# RL6678_IP_SVD register map
Vendor: Realtek
Registers are 32-bit, read-write, reset 0x0 unless marked. A register's access mark holds for its fields unless they carry their own. Offsets are from the block's base; [hi:lo] are bit positions; <NAME> marks a mode.

## REGU_REG
Base 0x42008100
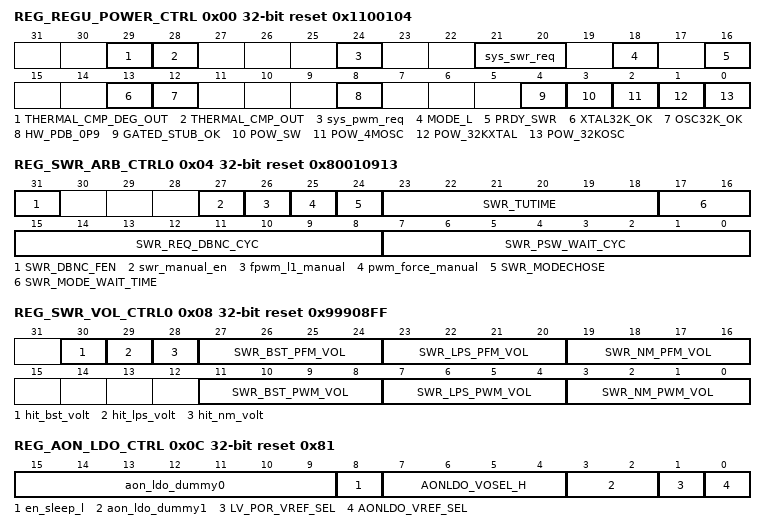
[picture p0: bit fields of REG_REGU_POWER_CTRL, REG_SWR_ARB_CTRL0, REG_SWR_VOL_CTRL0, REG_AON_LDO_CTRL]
0x00 REG_REGU_POWER_CTRL access per field reset 0x1100104
  [29] THERMAL_CMP_DEG_OUT ro — For SWR debug only
  [28] THERMAL_CMP_OUT ro — For SWR debug only
  [24] sys_pwm_req rw — system request SWR mode. 0: PFM 1: PWM
  [21:20] sys_swr_req rw — system request SWR voltage. 00: LPS vol 01: Normal vol 10/11: Burst vol
  [18] MODE_L ro — SWR current mode for debug
  [16] PRDY_SWR ro — SWR power ready flag by analog
  [13] XTAL32K_OK ro
  [12] OSC32K_OK ro — OSC128K ok
  [8] HW_PDB_0P9 rw — Digital control AIP 3.3v power down 1: enable 0: power down
  [4] GATED_STUB_OK rw — No used
  [3] POW_SW rw — 1: power SWR for digital core Note: this bit will be clear by bor/thm reset, and AON PMC will reboot.
  [2] POW_4MOSC rw — 1: power AON 4M osc
  [1] POW_32KXTAL rw — 1: power AON external 32xtal
  [0] POW_32KOSC rw — 1: power AON 128k osc for SDM
0x04 REG_SWR_ARB_CTRL0 reset 0x80010913
  [31] SWR_DBNC_FEN — SWR arb debounce enable
  [27] swr_manual_en — SWR manual mode enable. In manual mode,SWR's PFM vol value use normal pfm vol register,PWM vol use normal pwm vol register
  [26] fpwm_l1_manual — PWM/PFM manual (original fpwm_l1)
  [25] pwm_force_manual — force pwm bias manual (original pwm_force)
  [24] SWR_MODECHOSE — SWR arb voltage adjustment control signal option 0:arb internal signal 1:aip real signal
  [23:18] SWR_TUTIME — Because using AON 100k clock, this can set to 0
  [17:16] SWR_MODE_WAIT_TIME — 00: 50u 01: 100u 10: 250u 11: 500us
  [15:8] SWR_REQ_DBNC_CYC — Arbit dbc time for every step change . The real time is 10us * (this value + 1)
  [7:0] SWR_PSW_WAIT_CYC — Stable time for every step change . The real time is 10us * (this value + 1)
0x08 REG_SWR_VOL_CTRL0 access per field reset 0x99908FF
  [30] hit_bst_volt ro — Current voltage is in bst setting.
  [29] hit_lps_volt ro — Current voltage is in lps setting.
  [28] hit_nm_volt ro — Current voltage is in nm setting.
  [27:24] SWR_BST_PFM_VOL rw — Same as SWR_NM_PFM_VOL
  [23:20] SWR_LPS_PFM_VOL rw — Same as SWR_NM_PFM_VOL
  [19:16] SWR_NM_PFM_VOL rw — SWR/LDO 0000 0.752 0001 0.78 0010 0.801 0011 0.821 0100 0.841 0101 0.861 0110 0.881 0111 0.901 1000 0.921 1001 0.942 1010 0.963 1011 0.985 1100 1.010 1101 1.035 1110 1.062 1111 1.123
  [11:8] SWR_BST_PWM_VOL rw — Same as SWR_NM_PWM_VOL
  [7:4] SWR_LPS_PWM_VOL rw — Same as SWR_NM_PWM_VOL
  [3:0] SWR_NM_PWM_VOL rw — VREF 0.6V 0.575V 0000 0.711 0.682 0001 0.727 0.696 0010 0.761 0.730 0011 0.800 0.767 0100 0.833 0.798 0101 0.857 0.821 0110 0.881 0.844 0111 0.908 0.870 1000 0.937 0.898 1001 0.966 0.926 1010 1.000 0.958 1011 1.031 0.987 1100 1.063 1.018 1101 1.094 1.048 1110 1.123 1.076 1111 1.181 1.131
0x0C REG_AON_LDO_CTRL reset 0x81
  [15:9] aon_ldo_dummy0 — // [REGU][AONLDO] dummy
  [8] en_sleep_l — Enable LDO09H sleep mode 0 : disable (default) 1 : enable
  [7:4] AONLDO_VOSEL_H — AONLDO09 voltage select VREF 0P600V 0P575V 0000: 0.600V 0.575V 0001: 0.715V 0.685V 0010: 0.747V 0.716V 0011: 0.781V 0.749V 0100: 0.820V 0.786V 0101: 0.840V 0.806V 0110: 0.862V 0.826V 0111: 0.885V 0.848V 1000: 0.909V 0.871V 1001: 0.934V 0.896V 1010: 0.961V 0.921V 1011: 0.989V 0.949V 1100: 1.020V 0.977V 1101: 1.052V 1.009V 1110: 1.086V 1.041V 1111: 1.122V 1.076V
  [3:2] aon_ldo_dummy1 — // [REGU][AONLDO] dummy
  [1] LV_POR_VREF_SEL — LV_POR VREF 0 (default) VREF = 0P600V 1 VREF = 0P450V
  [0] AONLDO_VREF_SEL — AONLDO VREF_SEL 0 (default) VREF = 0P600V 1 VREF = 0P575V
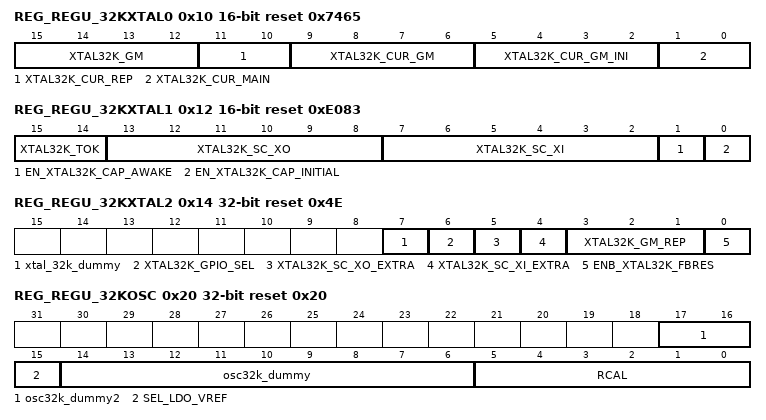
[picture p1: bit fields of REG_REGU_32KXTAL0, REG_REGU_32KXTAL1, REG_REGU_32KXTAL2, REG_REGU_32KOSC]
0x10 REG_REGU_32KXTAL0 16-bit reset 0x7465
  [15:12] XTAL32K_GM — // [RF][32KXTAL] REG_CTRL // gm size
  [11:10] XTAL32K_CUR_REP — // [RF][32KXTAL] REG_CTRL // replica buffer current
  [9:6] XTAL32K_CUR_GM — // [RF][32KXTAL] REG_CTRL // awake gm current, 7pXtal: 0100
  [5:2] XTAL32K_CUR_GM_INI — // [RF][32KXTAL] REG_CTRL // initial gm current, 7pXtal: 0100
  [1:0] XTAL32K_CUR_MAIN — // [RF][32KXTAL] REG_CTRL // xtal main current
0x12 REG_REGU_32KXTAL1 16-bit reset 0xE083
  [15:14] XTAL32K_TOK — // [RF][32KXTAL] REG_CTRL // 00: 100ms 01:200ms 10:400ms 11: 800ms
  [13:8] XTAL32K_SC_XO — // [RF][32KXTAL] REG_CTRL // xo cap
  [7:2] XTAL32K_SC_XI — // [RF][32KXTAL] REG_CTRL // xi cap
  [1] EN_XTAL32K_CAP_AWAKE — // [RF][32KXTAL] REG_CTRL // internal cap enable as awake
  [0] EN_XTAL32K_CAP_INITIAL — // [RF][32KXTAL] REG_CTRL // internal cap enable as initial
0x14 REG_REGU_32KXTAL2 reset 0x4E
  [7] xtal_32k_dummy — // [RF][32KXTAL] REG_CTRL // dummy
  [6] XTAL32K_GPIO_SEL — // [RF][32KXTAL] REG_CTRL // 0: 32K 1: GPIO
  [5] XTAL32K_SC_XO_EXTRA — // [RF][32KXTAL] REG_CTRL // 0: w/i 2.8pF cap 1: w/o 2.8pF cap
  [4] XTAL32K_SC_XI_EXTRA — // [RF][32KXTAL] REG_CTRL // 0: w/i 2.8pF cap 1: w/o 2.8pF cap
  [3:1] XTAL32K_GM_REP — // [RF][32KXTAL] REG_CTRL // repilca size
  [0] ENB_XTAL32K_FBRES — // [RF][32KXTAL] REG_CTRL // 0: enable feedback resistor
0x20 REG_REGU_32KOSC reset 0x20
  [17:16] osc32k_dummy2 — HW used only , these are for reserved
  [15] SEL_LDO_VREF — // [RF][32KOSC] REG_CTRL // 0: LDO low valtage setting 1:high voltage
  [14:6] osc32k_dummy — // [RF][32KOSC] REG_CTRL // dummy
  [5:0] RCAL — // [RF][32KOSC] REG_CTRL // osc frequency is highier as RCAL's larger
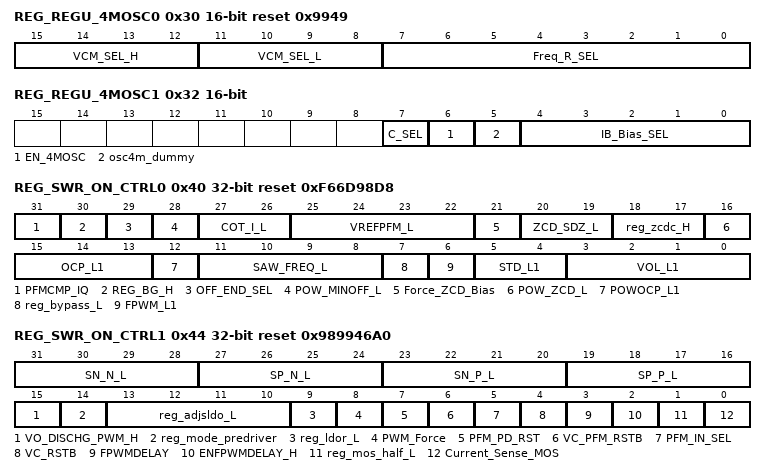
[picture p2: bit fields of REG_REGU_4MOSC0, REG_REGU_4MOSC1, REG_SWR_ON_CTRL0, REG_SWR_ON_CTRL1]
0x30 REG_REGU_4MOSC0 16-bit reset 0x9949
  [15:12] VCM_SEL_H — // [RF][4MOSC] REG_CTRL
  [11:8] VCM_SEL_L — // [RF][4MOSC] REG_CTRL
  [7:0] Freq_R_SEL — // [RF][4MOSC] REG_CTRL
0x32 REG_REGU_4MOSC1 16-bit access per field
  [7] C_SEL rw — // [RF][4MOSC] REG_CTRL
  [6] EN_4MOSC ro — // [RF][4MOSC] 1'b1 : enable Controlley by HW function .
  [5] osc4m_dummy rw — // [RF][4MOSC] REG_CTRL
  [4:0] IB_Bias_SEL rw — // [RF][4MOSC] REG_CTRL
0x40 REG_SWR_ON_CTRL0 access per field reset 0xF66D98D8
  [31] PFMCMP_IQ rw — PFM comparator bias 0: 50nA 1: 250nA
  [30] REG_BG_H rw — 1: VREF=0.6 0: VREF=0.575
  [29] OFF_END_SEL rw — COT off time controlled by 0: ZCD 1: min off time
  [28] POW_MINOFF_L rw — 0: normal current 1: increase OCP cmp current
  [27:26] COT_I_L rw — COT ON Current 00: 150nA 01: 150nA+100nA 10: 150nA+150nA 11: 150nA+250nA
  [25:22] VREFPFM_L ro — SWR/LDO 0000: 0.55 0001: 0.60 0010: 0.65 0011: 0.70 0100: 0.75 0101: 0.80 0110: 0.85 0111: 0.90 1000: 0.95 1001: 1.00 1010: 1.05 1011: 1.10 1100: 1.10 1101: 1.10 1110: 1.10 1111: 1.10
  [21] Force_ZCD_Bias rw — 0: ZCD bias on after SS 1: ZCD bias on when ZCD enable
  [20:19] ZCD_SDZ_L rw — Increase ZCD delay cell
  [18:17] reg_zcdc_H rw — 00: 0.1u 01: 0.2u(PFM) 10: 0.7u(PWM) 11: 0.8u PMW mode parameter when system is high load
  [16] POW_ZCD_L rw — Enable ZCD
  [15:13] OCP_L1 rw — PWM current(A) PFM current(A) mP 000 0.5712 0.0816 001 0.6528 0.1224 010 0.7344 0.1632 011 0.816 0.2448 100 0.8976 0.3264 101 0.9792 0.408 110 1.0608 0.4896 111 1.1424 VIN/10
  [12] POWOCP_L1 rw — POWOCP_L1=1=> enable over current protection
  [11:8] SAW_FREQ_L rw — 0000 458.0k 0001 680.2k 0010 898.9k 0011 1.113M 0100 1.321M 0101 1.522M 0110 1.716M 0111 1.902M 1000 2.087M 1001 2.258M 1010 2.426M 1011 2.582M 1100 2.743M 1101 2.888M 1110 3.035M 1111 3.165M PMW mode parameter when system is high load
  [7] reg_bypass_L rw — 1: bypass SSR latch
  [6] FPWM_L1 ro — FPWM_L1 = 1: force PWM FPWM_L1 = 0: force PFM
  [5:4] STD_L1 rw — STD_L1<1:0> time 750u 1.5m 10: 3m 11: 6m
  [3:0] VOL_L1 ro — VREF 0.6V 0.575V 0000 0.595 0.570 0001 0.709 0.679 0010 0.740 0.709 0011 0.774 0.742 0100 0.812 0.778 0101 0.833 0.798 0110 0.854 0.818 0111 0.876 0.840 1000 0.900 0.863 1001 0.925 0.886 1010 0.951 0.912 1011 0.979 0.939 1100 1.009 0.967 1101 1.041 0.997 1110 1.074 1.029 1111 1.110 1.064
0x44 REG_SWR_ON_CTRL1 access per field reset 0x989946A0
  [31:28] SN_N_L rw — NGATE NMOS driving
  [27:24] SP_N_L rw — NGATE PMOS driving
  [23:20] SN_P_L rw — PGATE NMOS driving
  [19:16] SP_P_L rw — PGATE PMOS driving
  [15] VO_DISCHG_PWM_H rw — 1: dummy loading 5mA
  [14] reg_mode_predriver rw — 1: 3 level predriver
  [13:10] reg_adjsldo_L rw — 0000: 0.735 0001: 0.742 0010: 0.750 0011: 0.766 0100: 0.783 0101: 0.800 0110: 0.818 0111: 0.837 1000: 0.857 1001: 0.878 1010: 0.900 1011: 0.923 1100: 0.947 1101: 0.973 1110: 1.029 1111: 1.091
  [9] reg_ldor_L rw — 1: ldos res short
  [8] PWM_Force ro — 0: PWM bias enabled only at PWM mode 1: Force PWM bias enable when in PWM/PFM mode
  [7] PFM_PD_RST rw — 1: When leave PFM mode, COT logic is reset
  [6] VC_PFM_RSTB rw — When into PFM, VC is 0: clamped (bit 40 also =1) 1: floating
  [5] PFM_IN_SEL rw — Power MOS into PFM when PFM CTRL, 0: rising 1: falling
  [4] VC_RSTB rw — Before SS VC is 0: pulled low 1: floating
  [3] FPWMDELAY rw — 1: PFM<=>PWM PFM/PWM change by using DFF (CKMOD)
  [2] ENFPWMDELAY_H rw — 1: PFM=>PWM delay PWM enable and wait one clock cycle then PFM off
  [1] reg_mos_half_L rw — 1: power mos half PMW mode parameter when system is high load
  [0] Current_Sense_MOS rw — 1: current sensing MOS for large OC current
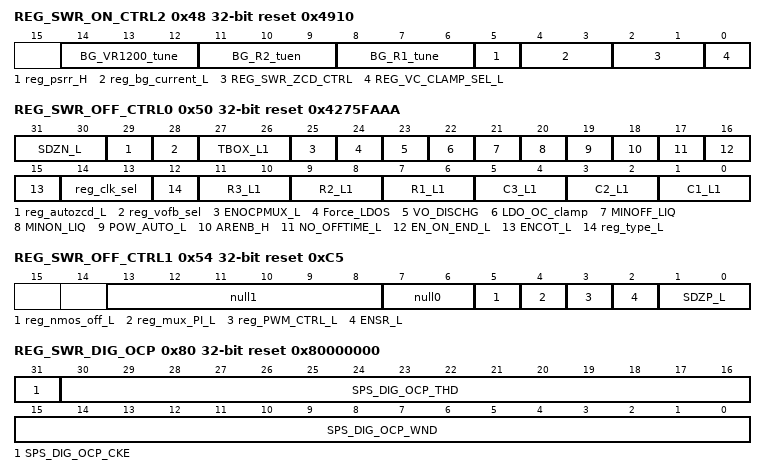
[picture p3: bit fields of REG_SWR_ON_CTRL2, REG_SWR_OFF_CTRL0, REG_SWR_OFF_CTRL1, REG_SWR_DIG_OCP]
0x48 REG_SWR_ON_CTRL2 reset 0x4910
  [14:12] BG_VR1200_tune — BG
  [11:9] BG_R2_tuen — BG R2
  [8:6] BG_R1_tune — BG R1
  [5] reg_psrr_H — 0: default 1: res+cap PMW mode parameter when system is high load
  [4:3] reg_bg_current_L — 00: 23.9n 01: 54.6n 10: 117.8n
  [2:1] REG_SWR_ZCD_CTRL — // SWR ZCD CTRL control <1>1: double current <0>1'b1: force in CCM/DCM boundary mode(default), 1'b0 : no boundary PMW mode parameter when system is high load
  [0] REG_VC_CLAMP_SEL_L — 0: unity gain feedback clamp VC=VREF 1: orignal clamp (roll back option)
0x50 REG_SWR_OFF_CTRL0 reset 0x4275FAAA
  [31:30] SDZN_L — Nonoverlap delay cell for NMOS
  [29] reg_autozcd_L — 0: register 1: 10000
  [28] reg_vofb_sel — 0: vo15 1: LX_SPS
  [27:26] TBOX_L1 — TBOX_L1<1:0> output 00: CKOVER/RAMPOVER 01: NI/PI 10: CKSS/SSOVER 11: i/NIOFF_H
  [25] ENOCPMUX_L — 1: OCP signal control by MUX 0: OCP signal control by I
  [24] Force_LDOS — 1: LDOS force on
  [23] VO_DISCHG — 1: VO with 1mA discharge
  [22] LDO_OC_clamp — 0: OC clamp with P/NMOS 1: OC clamp with PMOS
  [21] MINOFF_LIQ — 0: Min. off circuit always on 1: Min. off circuit pulse on
  [20] MINON_LIQ — 0: Min. on circuit always on 1: Min. on circuit pulse on
  [19] POW_AUTO_L — 1: auto PFM/PWM 0: register control
  [18] ARENB_H — 1: off 0: on
  [17] NO_OFFTIME_L — 0: from min OFF time(PFM COT) 1: always on
  [16] EN_ON_END_L — 1: EN min OFF time (PFM COT)
  [15] ENCOT_L — 1: PFM COT
  [14:13] reg_clk_sel — 00: out of phase CKSS 01: out of phase PWM_CTRIL 10: ckout 11: HG
  [12] reg_type_L — 1: type3 0: type2
  [11:10] R3_L1 — 00: 36k 01: 30k 10: 24k 11: 24k
  [9:8] R2_L1 — 00: 0.4M 01: 0.3M 10: 0.2M 11: 0.1M
  [7:6] R1_L1 — 00: 900k 01: 720k 10: 900k 11: 1080k
  [5:4] C3_L1 — 00: 1.59p 01: 3.2p 10: 4.76p 11: 6.34p
  [3:2] C2_L1 — 00: 13f 01: 26f 10: 39f 11: 41f
  [1:0] C1_L1 — 00: 1.03p 01: 2.06p 10: 3.1p 11: 4.12p
0x54 REG_SWR_OFF_CTRL1 reset 0xC5
  [13:8] null1 — HW used only , these are for reserved
  [7:6] null0 — HW used only , these are for reserved
  [5] reg_nmos_off_L — 0: normal 1: NMOS always off PMW mode parameter when system is high load
  [4] reg_mux_PI_L — 1: PI (original) 0: i
  [3] reg_PWM_CTRL_L — 0: internal PWM 1: external PWM
  [2] ENSR_L — 1: with SSR latch
  [1:0] SDZP_L — Nonoverlap delay cell for PMOS
0x80 REG_SWR_DIG_OCP reset 0x80000000
  [31] SPS_DIG_OCP_CKE — SPS OCP clock enable
  [30:16] SPS_DIG_OCP_THD — SPS OCP event threshold
  [15:0] SPS_DIG_OCP_WND — SPS OCP time window
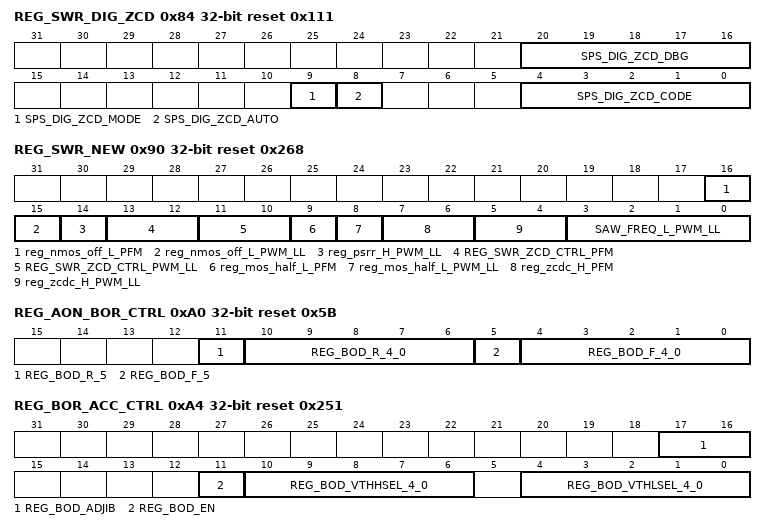
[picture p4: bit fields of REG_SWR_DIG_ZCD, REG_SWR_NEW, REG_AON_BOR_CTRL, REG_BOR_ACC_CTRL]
0x84 REG_SWR_DIG_ZCD access per field reset 0x111
  [20:16] SPS_DIG_ZCD_DBG ro — The acture zcd code used for SPS core
  [9] SPS_DIG_ZCD_MODE rw — SPS ZCD SW mode enable
  [8] SPS_DIG_ZCD_AUTO rw — SPS HW ZCD code auto count function enable
  [4:0] SPS_DIG_ZCD_CODE rw — SPS_DIG_ZCD_CODE,this is used for SW mode
0x90 REG_SWR_NEW reset 0x268
  [16] reg_nmos_off_L_PFM — 0: normal 1: NMOS always off PFM mode parametr
  [15] reg_nmos_off_L_PWM_LL — 0: normal 1: NMOS always off PWM mode parametr for system low load
  [14] reg_psrr_H_PWM_LL — 0: default 1: res+cap PWM mode parametr for system low load
  [13:12] REG_SWR_ZCD_CTRL_PFM — // SWR ZCD CTRL control <1>1: double current <0>1'b1: force in CCM/DCM boundary mode (default) 1'b0: no boundary PFM mode parametr
  [11:10] REG_SWR_ZCD_CTRL_PWM_LL — // SWR ZCD CTRL control <1>1: double current <0>1'b1: force in CCM/DCM boundary mode (default) 1'b0: no boundary PWM mode parametr for system low load
  [9] reg_mos_half_L_PFM — 1: power mos half PFM mode parametr
  [8] reg_mos_half_L_PWM_LL — 1: power mos half PWM mode parametr for system low load
  [7:6] reg_zcdc_H_PFM — 00: 0.1u 01: 0.2u (PFM) 10: 0.7u (PWM) 11: 0.8u PFM mode parametr
  [5:4] reg_zcdc_H_PWM_LL — 00: 0.1u 01: 0.2u (PFM) 10: 0.7u (PWM) 11: 0.8u PWM mode parametr for system low load
  [3:0] SAW_FREQ_L_PWM_LL — 0000: 458.0K 0001: 680.2K 0010: 898.9K 0011: 1.113M 0100: 1.321M 0101: 1.522M 0110: 1.716M 0111: 1.902M 1000: 2.087M 1001: 2.258M 1010: 2.426M 1011: 2.582M 1100: 2.743M 1101: 2.888M 1110: 3.035M 1111: 3.165M PWM mode parametr for system low load
0xA0 REG_AON_BOR_CTRL reset 0x5B
  [11] REG_BOD_R_5 — // 0: disable BOD // 1: enable BOD
  [10:6] REG_BOD_R_4_0 — 00000: 3.3333 00001: 3.2877 00010: 3.2432 00011: 3.2000 00100: 3.1579 00101: 3.1035 00110: 3.0508 00111: 3.0000 01000: 2.9508 01001: 2.9032 01010: 2.8571 01011: 2.8125 01100: 2.7692 01101: 2.7169 01110: 2.6666 01111: 2.6182 10000: 2.5623 10001: 2.5087 10010: 2.4574 10011: 2.4080 10100: 2.3606 10101: 2.3151 10110: 2.2713 10111: 2.2154 11000: 2.1621 11001: 2.1114 11010: 2.0630 11011: 2.0168 11100: 1.9672 11101: 1.9098 11110: 1.8556 11111: 1.8045
  [5] REG_BOD_F_5 — // dummy
  [4:0] REG_BOD_F_4_0 — 00000: 3.3333 00001: 3.2877 00010: 3.2432 00011: 3.2000 00100: 3.1579 00101: 3.1035 00110: 3.0508 00111: 3.0000 01000: 2.9508 01001: 2.9032 01010: 2.8571 01011: 2.8125 01100: 2.7692 01101: 2.7169 01110: 2.6666 01111: 2.6182 10000: 2.5623 10001: 2.5087 10010: 2.4574 10011: 2.4080 10100: 2.3606 10101: 2.3151 10110: 2.2713 10111: 2.2154 11000: 2.1621 11001: 2.1114 11010: 2.0630 11011: 2.0168 11100: 1.9672 11101: 1.9098 11110: 1.8556 11111: 1.8045
0xA4 REG_BOR_ACC_CTRL reset 0x251
  [17:16] REG_BOD_ADJIB — TODO
  [11] REG_BOD_EN — // 0: disable SYS high accuracy BOD // 1: enable SYS high accuracy BOD
  [10:6] REG_BOD_VTHHSEL_4_0 — 00000: 3.3333 00001: 3.2877 00010: 3.2432 00011: 3.2000 00100: 3.1579 00101: 3.1035 00110: 3.0508 00111: 3.0000 01000: 2.9508 01001: 2.9032 01010: 2.8571 01011: 2.8125 01100: 2.7692 01101: 2.7169 01110: 2.6666 01111: 2.6182 10000: 2.5623 10001: 2.5087 10010: 2.4574 10011: 2.4080 10100: 2.3606 10101: 2.3151 10110: 2.2713 10111: 2.2154 11000: 2.1621 11001: 2.1114 11010: 2.0630 11011: 2.0168 11100: 1.9672 11101: 1.9098 11110: 1.8556 11111: 1.8045
  [4:0] REG_BOD_VTHLSEL_4_0 — 00000: 3.3333 00001: 3.2877 00010: 3.2432 00011: 3.2000 00100: 3.1579 00101: 3.1035 00110: 3.0508 00111: 3.0000 01000: 2.9508 01001: 2.9032 01010: 2.8571 01011: 2.8125 01100: 2.7692 01101: 2.7169 01110: 2.6666 01111: 2.6182 10000: 2.5623 10001: 2.5087 10010: 2.4574 10011: 2.4080 10100: 2.3606 10101: 2.3151 10110: 2.2713 10111: 2.2154 11000: 2.1621 11001: 2.1114 11010: 2.0630 11011: 2.0168 11100: 1.9672 11101: 1.9098 11110: 1.8556 11111: 1.8045
0xA8 REG_AON_POW_32K
  [15:0] REG_POW_32K — HW used only , these are for reserved
0xAC REG_DUMMY
  [5:0] reg_dummy_l
